# TC37X register map
File version: 1.0.0
CPU: CM4 r0p1, little endian, MPU, FPU, VTOR, 3 interrupt priority bits
Registers are 16-bit, read-write, reset 0x0 unless marked. A register's access mark holds for its fields unless they carry their own. Offsets are from the block's base; [hi:lo] are bit positions; {n}, {i} and the like mark numbered series; 'fields as' and 'values as' point back to an identical list.

## port_12 — eneral Purpose I/O Ports and Peripheral I/O Lines
Base 0xF003AC00
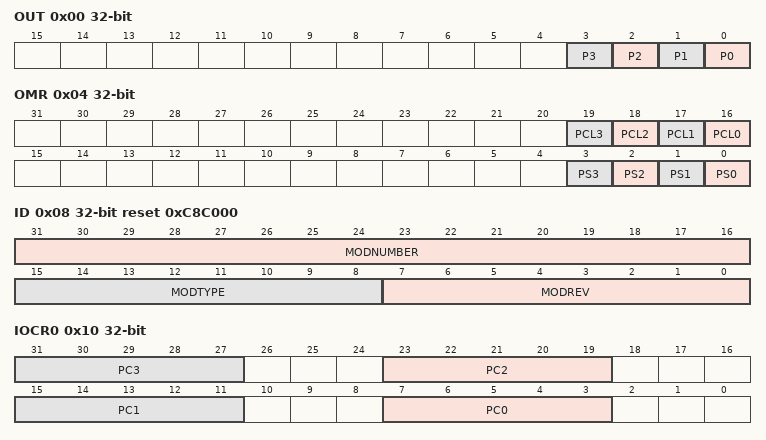
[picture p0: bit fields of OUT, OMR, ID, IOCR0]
0x00 OUT 32-bit — Port 12 Output Register
  [n] P{n} (n=0..3) — Output Bit {n}
0x04 OMR 32-bit — Port 12 Output Modification Register
  [n+16] PCL{n} wo (n=0..3) — Clear Bit {n}
  [n] PS{n} wo (n=0..3) — Set Bit {n}
0x08 ID 32-bit ro reset 0xC8C000 (reset mask 0xFFFFFF00) — Port 12 Identification Register
  [31:16] MODNUMBER — Module Number
  [15:8] MODTYPE — Module Type
  [7:0] MODREV — Module Revision Number
0x10 IOCR0 32-bit — Port 12 Input/Output Control Register 0
  [8n+7:8n+3] PC{n} (n=0..3) — Port Control for Pin {n}
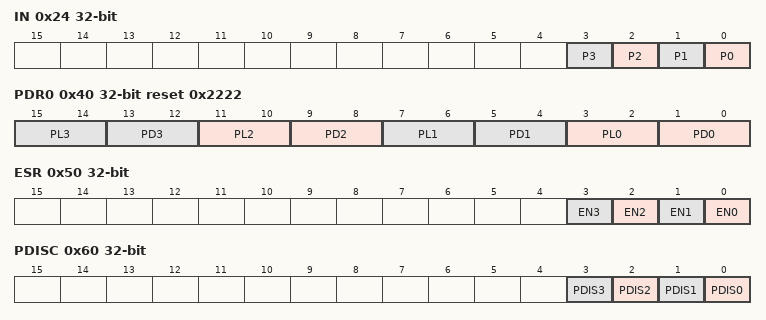
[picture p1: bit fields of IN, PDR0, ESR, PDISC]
0x24 IN 32-bit ro (reset mask 0xFFFFFFF0) — Port 12 Input Register
  [n] P{n} (n=0..3) — Input Bit {n}
0x40 PDR0 32-bit reset 0x2222 — Port 12 Pad Driver Mode Register 0
  [4n+3:4n+2] PL{n} (n=0..3) — Pad Level Selection for Pin {n}
  [4n+1:4n] PD{n} (n=0..3) — Pad Driver Mode for Pin {n}
0x50 ESR 32-bit — Port 12 Emergency Stop Register
  [n] EN{n} (n=0..3) — Emergency Stop Enable for Pin {n}
0x60 PDISC 32-bit — Port 12 Pin Function Decision Control Register
  [n] PDIS{n} (n=0..3) — Pin Function Decision Control for Pin {n}
0x64 PCSR 32-bit — Port 12 Pin Controller Select Register
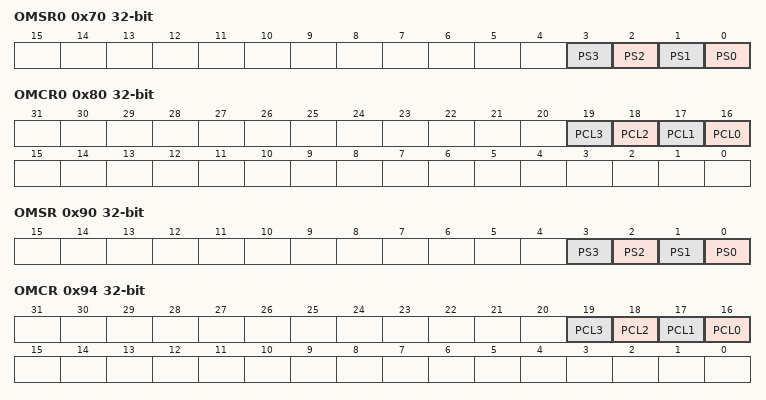
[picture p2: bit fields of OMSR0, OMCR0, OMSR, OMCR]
0x70 OMSR0 32-bit — Port 12 Output Modification Set Register 0
  [n] PS{n} wo (n=0..3) — Set Bit {n}
0x80 OMCR0 32-bit — Port 12 Output Modification Clear Register 0
  [n+16] PCL{n} wo (n=0..3) — Clear Bit {n}
0x90 OMSR 32-bit — Port 12 Output Modification Set Register
  [n] PS{n} wo (n=0..3) — Set Bit {n}
0x94 OMCR 32-bit — Port 12 Output Modification Clear Register
  [n+16] PCL{n} wo (n=0..3) — Clear Bit {n}
0xF8 ACCEN1 32-bit ro — Port 12 Access Enable Register 1
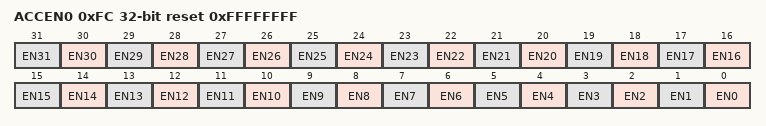
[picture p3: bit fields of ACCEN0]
0xFC ACCEN0 32-bit reset 0xFFFFFFFF — Port 12 Access Enable Register 0
  [n] EN{n} (n=0..31) — Access Enable for Master TAG ID {n}

## port_13 — eneral Purpose I/O Ports and Peripheral I/O Lines
Base 0xF003AD00
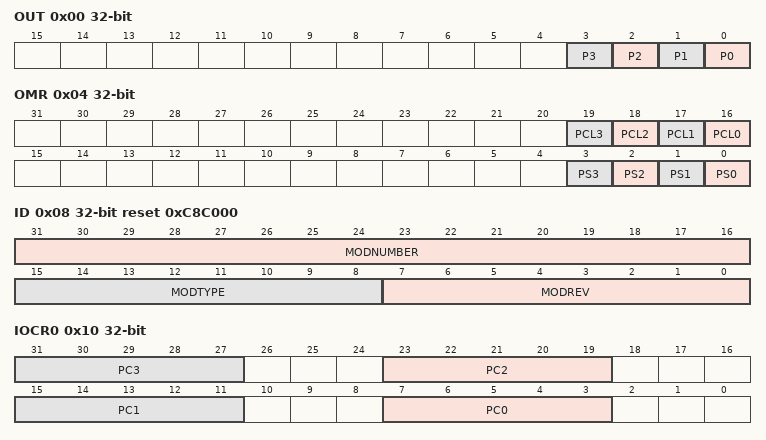
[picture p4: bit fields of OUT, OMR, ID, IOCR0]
0x00 OUT 32-bit — Port 13 Output Register
  [n] P{n} (n=0..3) — Output Bit {n}
0x04 OMR 32-bit — Port 13 Output Modification Register
  [n+16] PCL{n} wo (n=0..3) — Clear Bit {n}
  [n] PS{n} wo (n=0..3) — Set Bit {n}
0x08 ID 32-bit ro reset 0xC8C000 (reset mask 0xFFFFFF00) — Port 13 Identification Register
  [31:16] MODNUMBER — Module Number
  [15:8] MODTYPE — Module Type
  [7:0] MODREV — Module Revision Number
0x10 IOCR0 32-bit — Port 13 Input/Output Control Register 0
  [8n+7:8n+3] PC{n} (n=0..3) — Port Control for Pin {n}
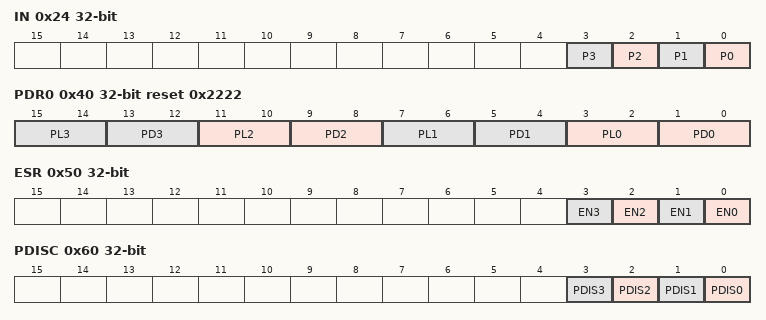
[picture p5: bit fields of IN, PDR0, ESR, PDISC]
0x24 IN 32-bit ro (reset mask 0xFFFFFFF0) — Port 13 Input Register
  [n] P{n} (n=0..3) — Input Bit {n}
0x40 PDR0 32-bit reset 0x2222 — Port 13 Pad Driver Mode Register 0
  [4n+3:4n+2] PL{n} (n=0..3) — Pad Level Selection for Pin {n}
  [4n+1:4n] PD{n} (n=0..3) — Pad Driver Mode for Pin {n}
0x50 ESR 32-bit — Port 13 Emergency Stop Register
  [n] EN{n} (n=0..3) — Emergency Stop Enable for Pin {n}
0x60 PDISC 32-bit — Port 13 Pin Function Decision Control Register
  [n] PDIS{n} (n=0..3) — Pin Function Decision Control for Pin {n}
0x64 PCSR 32-bit — Port 13 Pin Controller Select Register
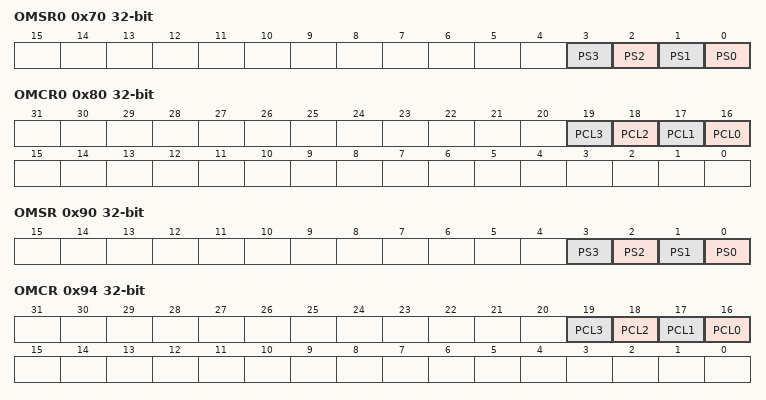
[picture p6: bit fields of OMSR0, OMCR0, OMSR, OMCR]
0x70 OMSR0 32-bit — Port 13 Output Modification Set Register 0
  [n] PS{n} wo (n=0..3) — Set Bit {n}
0x80 OMCR0 32-bit — Port 13 Output Modification Clear Register 0
  [n+16] PCL{n} wo (n=0..3) — Clear Bit {n}
0x90 OMSR 32-bit — Port 13 Output Modification Set Register
  [n] PS{n} wo (n=0..3) — Set Bit {n}
0x94 OMCR 32-bit — Port 13 Output Modification Clear Register
  [n+16] PCL{n} wo (n=0..3) — Clear Bit {n}
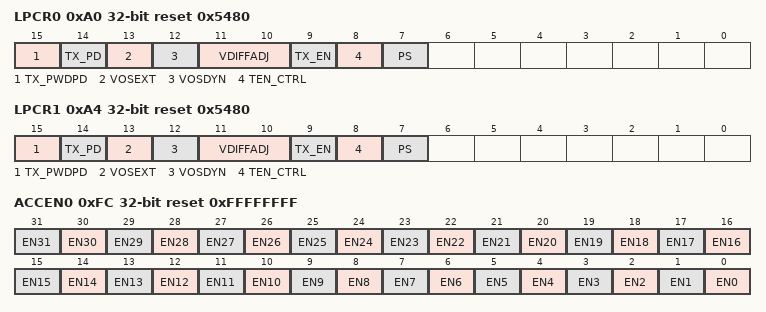
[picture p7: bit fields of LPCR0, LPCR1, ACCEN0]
0xA0 LPCR0 32-bit reset 0x5480 — Port 13 LVDS Pad Control Register 0
  [15] TX_PWDPD — Enable TX Power down pull down.
  [14] TX_PD — LVDS Power Down
  [13] VOSEXT — Tune Bit of VOS Control Loop Internal/External
  [12] VOSDYN — Tune Bit of VOS Control Loop Static/Dynamic
  [11:10] VDIFFADJ — LVDS Output Amplitude Tuning
  [9] TX_EN — Enable Transmit LVDS
  [8] TEN_CTRL — LVDS TX_EN controller
  [7] PS — Pad Supply Selection
0xA4 LPCR1 32-bit reset 0x5480 — Port 13 LVDS Pad Control Register 1
  fields as LPCR0
0xF8 ACCEN1 32-bit ro — Port 13 Access Enable Register 1
0xFC ACCEN0 32-bit reset 0xFFFFFFFF — Port 13 Access Enable Register 0
  [n] EN{n} (n=0..31) — Access Enable for Master TAG ID {n}
